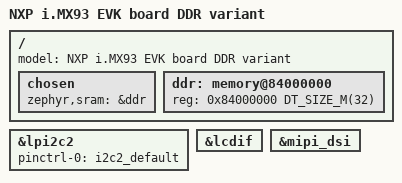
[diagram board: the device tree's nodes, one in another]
/*
 * Copyright 2024-2025 NXP
 *
 * SPDX-License-Identifier: Apache-2.0
 */

/dts-v1/;

#include "imx93_evk_mimx9352_m33.dts"
#include <dt-bindings/mipi_dsi/mipi_dsi.h>

/ {
	model = "NXP i.MX93 EVK board DDR variant";

	chosen {
		zephyr,sram = &ddr;
		/delete-property/ zephyr,flash;
	};

	ddr: memory@84000000 {
		device_type = "memory";
		reg = <0x84000000 DT_SIZE_M(32)>;
	};
};

&lpi2c2 {
	pinctrl-0 = <&i2c2_default>;
	pinctrl-names = "default";
	status = "okay";
};

zephyr_lcdif: &lcdif {};

display_i2c: &lpi2c2 {};

zephyr_mipi_dsi: &mipi_dsi {};
